VERSION ""

NS_ :

BS_:

BU_: Beifahrersitz Fahrersitz FondtuerLinks Innenlicht System

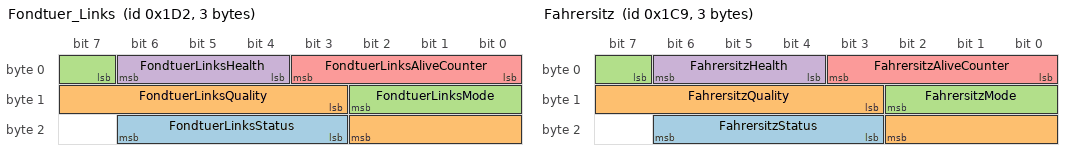
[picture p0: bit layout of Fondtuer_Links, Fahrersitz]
BO_ 466 Fondtuer_Links: 3 FondtuerLinks
 SG_ FondtuerLinksStatus : 19|4@1+ (1,0) [0.0|15.0] "code"  System
 SG_ FondtuerLinksQuality : 11|8@1+ (0.5,0.0) [0.0|100.0] "%"  System
 SG_ FondtuerLinksMode : 7|4@1+ (1,0) [0.0|15.0] "code"  System
 SG_ FondtuerLinksHealth : 4|3@1+ (1,0) [0.0|7.0] "code"  System
 SG_ FondtuerLinksAliveCounter : 0|4@1+ (1,0) [0.0|15.0] "count"  System

BO_ 457 Fahrersitz: 3 Fahrersitz
 SG_ FahrersitzStatus : 19|4@1+ (1,0) [0.0|15.0] "code"  System
 SG_ FahrersitzQuality : 11|8@1+ (0.5,0.0) [0.0|100.0] "%"  System
 SG_ FahrersitzMode : 7|4@1+ (1,0) [0.0|15.0] "code"  System
 SG_ FahrersitzHealth : 4|3@1+ (1,0) [0.0|7.0] "code"  System
 SG_ FahrersitzAliveCounter : 0|4@1+ (1,0) [0.0|15.0] "count"  System

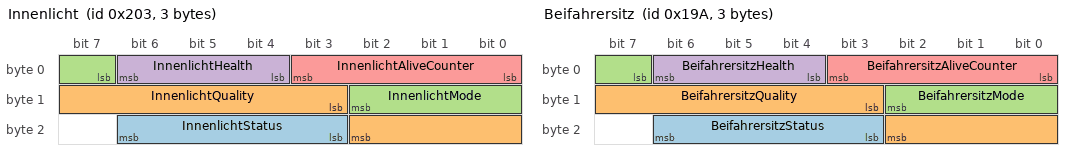
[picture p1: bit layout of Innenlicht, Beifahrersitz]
BO_ 515 Innenlicht: 3 Innenlicht
 SG_ InnenlichtStatus : 19|4@1+ (1,0) [0.0|15.0] "code"  System
 SG_ InnenlichtQuality : 11|8@1+ (0.5,0.0) [0.0|100.0] "%"  System
 SG_ InnenlichtMode : 7|4@1+ (1,0) [0.0|15.0] "code"  System
 SG_ InnenlichtHealth : 4|3@1+ (1,0) [0.0|7.0] "code"  System
 SG_ InnenlichtAliveCounter : 0|4@1+ (1,0) [0.0|15.0] "count"  System

BO_ 410 Beifahrersitz: 3 Beifahrersitz
 SG_ BeifahrersitzStatus : 19|4@1+ (1,0) [0.0|15.0] "code"  System
 SG_ BeifahrersitzQuality : 11|8@1+ (0.5,0.0) [0.0|100.0] "%"  System
 SG_ BeifahrersitzMode : 7|4@1+ (1,0) [0.0|15.0] "code"  System
 SG_ BeifahrersitzHealth : 4|3@1+ (1,0) [0.0|7.0] "code"  System
 SG_ BeifahrersitzAliveCounter : 0|4@1+ (1,0) [0.0|15.0] "count"  System

CM_ BO_ 466 "CanonicalMessage=a1a2284e-f448-4c8a-ae11-48da44561db6; Network=Karosserie_Komfort_06-S01-CAP-S03; Technology=can_fd";
CM_ SG_ 466 FondtuerLinksStatus "CanonicalSignal=4a7e8621-4572-406d-9e3c-af0447db923f";
CM_ SG_ 466 FondtuerLinksQuality "CanonicalSignal=89a2580d-27a8-4d2c-a79b-7abceefa3ee1";
CM_ SG_ 466 FondtuerLinksMode "CanonicalSignal=29a9e26d-384a-48fe-af18-123a4cca91fb";
CM_ SG_ 466 FondtuerLinksHealth "CanonicalSignal=bdfd1e23-d212-4fb5-b1fd-56544fe4b323";
CM_ SG_ 466 FondtuerLinksAliveCounter "CanonicalSignal=d51b32ad-8eab-4e0b-9b71-6a88961c82cf";
CM_ BO_ 457 "CanonicalMessage=bd2c75df-644e-420f-bc34-debf42658af2; Network=Karosserie_Komfort_06-S01-CAP-S03; Technology=can_fd";
CM_ SG_ 457 FahrersitzStatus "CanonicalSignal=928e56e1-a8b1-4073-aa1a-cffa57d5c6c0";
CM_ SG_ 457 FahrersitzQuality "CanonicalSignal=c793cc2a-ae52-4a8c-87ba-9b7764307e60";
CM_ SG_ 457 FahrersitzMode "CanonicalSignal=a034a223-de29-4dc3-ac4f-8cafee726c43";
CM_ SG_ 457 FahrersitzHealth "CanonicalSignal=35a4f0ab-2796-45fe-bd49-9cc01659fd51";
CM_ SG_ 457 FahrersitzAliveCounter "CanonicalSignal=61991164-083a-4c42-b06f-20a06ff357f1";
CM_ BO_ 515 "CanonicalMessage=64ae7560-8b92-46e4-aec8-edf6aa857c18; Network=Karosserie_Komfort_06-S01-CAP-S03; Technology=can_fd";
CM_ SG_ 515 InnenlichtStatus "CanonicalSignal=c0f6fac3-7e02-4350-93f6-4cceb64847b1";
CM_ SG_ 515 InnenlichtQuality "CanonicalSignal=05dc2da3-0b81-43bf-812b-71be6da75097";
CM_ SG_ 515 InnenlichtMode "CanonicalSignal=2656a688-fa62-4ea6-a01c-b730920881b1";
CM_ SG_ 515 InnenlichtHealth "CanonicalSignal=c566fe87-35da-4797-a69f-cac49134745c";
CM_ SG_ 515 InnenlichtAliveCounter "CanonicalSignal=b292f4ff-7162-4a69-be53-82559f9353a6";
CM_ BO_ 410 "CanonicalMessage=2d522485-603f-4edf-ab33-57b42d311462; Network=Karosserie_Komfort_06-S01-CAP-S03; Technology=can_fd";
CM_ SG_ 410 BeifahrersitzStatus "CanonicalSignal=e4f31f6c-2c43-4985-9d7b-961d4ff11abd";
CM_ SG_ 410 BeifahrersitzQuality "CanonicalSignal=1a6282d5-e0cb-48e2-bf10-c6f20da245f0";
CM_ SG_ 410 BeifahrersitzMode "CanonicalSignal=adcca924-338b-4496-97d5-caba92555b0e";
CM_ SG_ 410 BeifahrersitzHealth "CanonicalSignal=5011e9f0-91e0-4b99-96f0-925ba62c4b07";
CM_ SG_ 410 BeifahrersitzAliveCounter "CanonicalSignal=ae1f69c1-c864-4bce-a710-b39125d299d7";
BA_DEF_ BO_  "VFrameFormat" ENUM  "StandardCAN","ExtendedCAN","StandardCAN_FD","ExtendedCAN_FD";
BA_DEF_DEF_  "VFrameFormat" "0";
BA_ "VFrameFormat" BO_ 466 2;
BA_ "VFrameFormat" BO_ 457 2;
BA_ "VFrameFormat" BO_ 515 2;
BA_ "VFrameFormat" BO_ 410 2;
